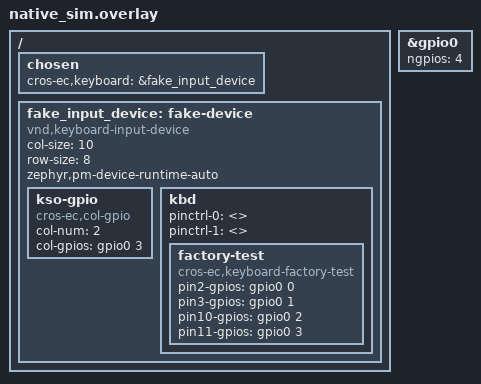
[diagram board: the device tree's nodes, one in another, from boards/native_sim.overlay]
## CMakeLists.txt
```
# Copyright 2024 The ChromiumOS Authors
# Use of this source code is governed by a BSD-style license that can be
# found in the LICENSE file.

cmake_minimum_required(VERSION 3.13.1)
find_package(Zephyr REQUIRED HINTS "${ZEPHYR_BASE}")
project(keyboard_factory_test)

zephyr_include_directories("${CMAKE_CURRENT_SOURCE_DIR}/include")

target_sources(app PRIVATE ../../../chip/host/lpc.c)

target_sources(app PRIVATE src/main.c)
```

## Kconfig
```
# Copyright 2024 The ChromiumOS Authors
# Use of this source code is governed by a BSD-style license that can be
# found in the LICENSE file.

config INPUT_KBD_MATRIX
	default y

source "Kconfig.zephyr"
```

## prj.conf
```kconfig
# Copyright 2024 The ChromiumOS Authors
# Use of this source code is governed by a BSD-style license that can be
# found in the LICENSE file.

CONFIG_ZTEST=y
CONFIG_GPIO=y
CONFIG_SERIAL=y
CONFIG_PINCTRL=y

CONFIG_INPUT=y
CONFIG_INPUT_MODE_SYNCHRONOUS=y
CONFIG_PM_DEVICE=y
CONFIG_PM_DEVICE_RUNTIME=y
CONFIG_SHELL=y
CONFIG_SHELL_BACKEND_DUMMY=y
CONFIG_SHELL_BACKEND_SERIAL=n

CONFIG_PLATFORM_EC=y
CONFIG_CROS_EC=y
CONFIG_SHIMMED_TASKS=y

CONFIG_PLATFORM_EC_HOSTCMD=y

CONFIG_PLATFORM_EC_VBOOT_HASH=n
CONFIG_PLATFORM_EC_SWITCH=n
```

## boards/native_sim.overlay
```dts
/* Copyright 2023 The ChromiumOS Authors
 * Use of this source code is governed by a BSD-style license that can be
 * found in the LICENSE file.
 */

#include <board-overlays/native_sim.dts>

/ {
        chosen {
                cros-ec,keyboard = &fake_input_device;
        };

	fake_input_device: fake-device {
		compatible = "vnd,keyboard-input-device";
		col-size = <10>;
		row-size = <8>;
		zephyr,pm-device-runtime-auto;

		kso-gpio {
			compatible = "cros-ec,col-gpio";
			col-num = <2>;
			col-gpios = <&gpio0 3 GPIO_ACTIVE_HIGH>;
		};

		kbd {
			pinctrl-0 = <>;
			pinctrl-1 = <>;
			pinctrl-names = "default", "sleep";

			factory-test {
				compatible = "cros-ec,keyboard-factory-test";

				pin2-gpios = <&gpio0 0 GPIO_ACTIVE_HIGH>;
				pin3-gpios = <&gpio0 1 GPIO_ACTIVE_HIGH>;
				pin10-gpios = <&gpio0 2 GPIO_ACTIVE_HIGH>;
				pin11-gpios = <&gpio0 3 GPIO_ACTIVE_HIGH>;
			};
		};

	};
};

&gpio0 {
        ngpios = <4>;
};
```

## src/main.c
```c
/* Copyright 2024 The ChromiumOS Authors
 * Use of this source code is governed by a BSD-style license that can be
 * found in the LICENSE file.
 */

#include "host_command.h"
#include "keyboard_scan.h"
#include "system.h"

#include <zephyr/device.h>
#include <zephyr/drivers/gpio.h>
#include <zephyr/drivers/gpio/gpio_emul.h>
#include <zephyr/drivers/pinctrl.h>
#include <zephyr/fff.h>
#include <zephyr/input/input.h>
#include <zephyr/input/input_kbd_matrix.h>
#include <zephyr/pm/device.h>
#include <zephyr/pm/device_runtime.h>
#include <zephyr/shell/shell_dummy.h>
#include <zephyr/sys/util.h>
#include <zephyr/ztest.h>

DEFINE_FFF_GLOBALS;

FAKE_VALUE_FUNC(int, vnd_keyboard_pm_action, const struct device *,
		enum pm_device_action);
FAKE_VALUE_FUNC(int, pinctrl_configure_pins, const pinctrl_soc_pin_t *, uint8_t,
		uintptr_t);
FAKE_VALUE_FUNC(int, system_is_locked);
FAKE_VOID_FUNC(test_drive_column, const struct device *, int);
FAKE_VALUE_FUNC(kbd_row_t, test_read_row, const struct device *);
FAKE_VOID_FUNC(test_set_detect_mode, const struct device *, bool);
FAKE_VALUE_FUNC(int, mkbp_keyboard_add, const uint8_t *);

static const struct input_kbd_matrix_api test_api = {
	.drive_column = test_drive_column,
	.read_row = test_read_row,
	.set_detect_mode = test_set_detect_mode,
};

#define VND_KEYBOARD_NODE DT_INST(0, vnd_keyboard_input_device)

INPUT_KBD_MATRIX_DT_DEFINE(VND_KEYBOARD_NODE);

static const struct input_kbd_matrix_common_config kbd_cfg =
	INPUT_KBD_MATRIX_DT_COMMON_CONFIG_INIT(VND_KEYBOARD_NODE, &test_api);

static struct input_kbd_matrix_common_data kbd_data;

PM_DEVICE_DT_DEFINE(VND_KEYBOARD_NODE, vnd_keyboard_pm_action);

DEVICE_DT_DEFINE(VND_KEYBOARD_NODE, input_kbd_matrix_common_init,
		 PM_DEVICE_DT_GET(VND_KEYBOARD_NODE), &kbd_data, &kbd_cfg,
		 POST_KERNEL, CONFIG_KERNEL_INIT_PRIORITY_DEVICE, NULL);

static const struct device *gpio_dev = DEVICE_DT_GET(DT_NODELABEL(gpio0));

#define FACTORY_TEST_NODE \
	DT_COMPAT_GET_ANY_STATUS_OKAY(cros_ec_keyboard_factory_test)
#define P2_GPIO_NUM DT_GPIO_PIN(FACTORY_TEST_NODE, pin2_gpios)
#define P3_GPIO_NUM DT_GPIO_PIN(FACTORY_TEST_NODE, pin3_gpios)
#define P10_GPIO_NUM DT_GPIO_PIN(FACTORY_TEST_NODE, pin10_gpios)
#define P11_GPIO_NUM DT_GPIO_PIN(FACTORY_TEST_NODE, pin11_gpios)

#define COL_GPIO_NODE DT_COMPAT_GET_ANY_STATUS_OKAY(cros_ec_col_gpio)
#define COL_GPIO_NUM DT_GPIO_PIN(COL_GPIO_NODE, col_gpios)

static bool simulate_short_p3_p11;

static void gpio_emul_cb_handler(const struct device *dev,
				 struct gpio_callback *gpio_cb, uint32_t pins)
{
	if (simulate_short_p3_p11 && pins == BIT(P3_GPIO_NUM)) {
		gpio_emul_input_set(gpio_dev, P11_GPIO_NUM, 0);
	}
}

static struct gpio_callback gpio_emul_cb;

ZTEST(keyboard_factory_test, test_factory_test_hc)
{
	struct ec_response_keyboard_factory_test resp;
	struct host_cmd_handler_args args = BUILD_HOST_COMMAND_RESPONSE(
		EC_CMD_KEYBOARD_FACTORY_TEST, 0, resp);
	gpio_flags_t flags;

	zassert_ok(host_command_process(&args));
	zassert_equal(args.response_size, sizeof(resp));
	zassert_equal(resp.shorted, 0);
	zassert_equal(pinctrl_configure_pins_fake.call_count, 2);

	gpio_emul_flags_get(gpio_dev, P10_GPIO_NUM, &flags);
	zassert_equal(flags, GPIO_INPUT | GPIO_PULL_UP);

	gpio_emul_flags_get(gpio_dev, COL_GPIO_NUM, &flags);
	zassert_equal(flags, GPIO_OUTPUT_LOW);
}

ZTEST(keyboard_factory_test, test_factory_test_hc_shorted)
{
	struct ec_response_keyboard_factory_test resp;
	struct host_cmd_handler_args args = BUILD_HOST_COMMAND_RESPONSE(
		EC_CMD_KEYBOARD_FACTORY_TEST, 0, resp);

	simulate_short_p3_p11 = true;

	zassert_ok(host_command_process(&args));
	zassert_equal(args.response_size, sizeof(resp));
	zassert_equal(resp.shorted, 3 << 8 | 11);
}

ZTEST(keyboard_factory_test, test_factory_test_locked)
{
	struct ec_response_keyboard_factory_test resp;
	struct host_cmd_handler_args args = BUILD_HOST_COMMAND_RESPONSE(
		EC_CMD_KEYBOARD_FACTORY_TEST, 0, resp);

	system_is_locked_fake.return_val = true;

	zassert_equal(host_command_process(&args), EC_RES_ACCESS_DENIED);
	zassert_equal(resp.shorted, 0);
	zassert_equal(pinctrl_configure_pins_fake.call_count, 0);
}

ZTEST(keyboard_factory_test, test_factory_test_shell)
{
	const struct shell *shell_zephyr = shell_backend_dummy_get_ptr();
	const char *outbuffer;
	size_t buffer_size;

	/* Give the backend time to initialize */
	k_sleep(K_MSEC(100));

	shell_backend_dummy_clear_output(shell_zephyr);

	zassert_ok(shell_execute_cmd(shell_zephyr, "kbfactorytest"));
	outbuffer = shell_backend_dummy_get_output(shell_zephyr, &buffer_size);
	zassert_true(buffer_size > 0, NULL);

	zassert_not_null(strstr(outbuffer,
				"Keyboard factory test: shorted=0000 (0, 0)"));
}

ZTEST(keyboard_factory_test, test_factory_test_shell_shorted)
{
	const struct shell *shell_zephyr = shell_backend_dummy_get_ptr();
	const char *outbuffer;
	size_t buffer_size;

	/* Give the backend time to initialize */
	k_sleep(K_MSEC(100));

	shell_backend_dummy_clear_output(shell_zephyr);

	simulate_short_p3_p11 = true;

	zassert_ok(shell_execute_cmd(shell_zephyr, "kbfactorytest"));
	outbuffer = shell_backend_dummy_get_output(shell_zephyr, &buffer_size);
	zassert_true(buffer_size > 0, NULL);

	zassert_not_null(strstr(outbuffer,
				"Keyboard factory test: shorted=030b (3, 11)"));
}

static void reset(void *fixture)
{
	ARG_UNUSED(fixture);

	RESET_FAKE(system_is_locked);
	RESET_FAKE(vnd_keyboard_pm_action);
	RESET_FAKE(pinctrl_configure_pins);
	RESET_FAKE(mkbp_keyboard_add);

	simulate_short_p3_p11 = false;
}

static void *keyboard_factory_test_setup(void)
{
	gpio_init_callback(&gpio_emul_cb, gpio_emul_cb_handler,
			   BIT(P2_GPIO_NUM) | BIT(P3_GPIO_NUM) |
				   BIT(P10_GPIO_NUM) | BIT(P11_GPIO_NUM));

	gpio_add_callback(gpio_dev, &gpio_emul_cb);

	return NULL;
}

ZTEST_SUITE(keyboard_factory_test, NULL, keyboard_factory_test_setup, reset,
	    reset, NULL);
```

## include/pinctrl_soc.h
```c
/* Copyright 2024 The ChromiumOS Authors
 * Use of this source code is governed by a BSD-style license that can be
 * found in the LICENSE file.
 */

struct pinctrl_soc_pin {
	uint32_t empty;
};

typedef struct pinctrl_soc_pin pinctrl_soc_pin_t;

#define Z_PINCTRL_STATE_PINS_INIT(node_id, prop) \
	{                                        \
	}
```
